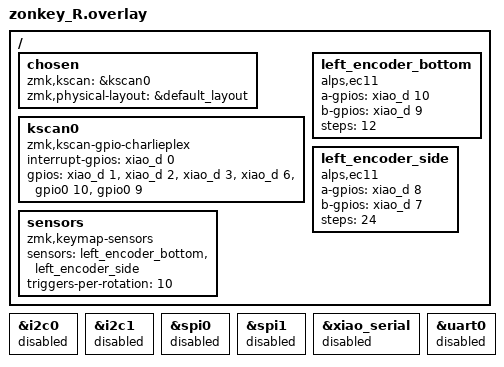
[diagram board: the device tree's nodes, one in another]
#include <dt-bindings/zmk/matrix_transform.h>
#include <dt-bindings/zmk/input_transform.h>
#include <input/processors.dtsi>
#include <zephyr/dt-bindings/input/input-event-codes.h>
#include <physical_layouts.dtsi>
#include "zk.dtsi"

/ {
    chosen {
        zmk,kscan = &kscan0;
        zmk,physical-layout = &default_layout;
        /* I2Cを削除したため zephyr,display は記述しません */
    };

    /* チャーリープレックス・マトリックス設定 */
    kscan0: kscan0 {
        compatible = "zmk,kscan-gpio-charlieplex";
        interrupt-gpios = <&xiao_d 0 (GPIO_ACTIVE_HIGH | GPIO_PULL_DOWN)>;
        gpios
            = <&xiao_d 1 GPIO_ACTIVE_HIGH>
            , <&xiao_d 2 GPIO_ACTIVE_HIGH>
            , <&xiao_d 3 GPIO_ACTIVE_HIGH>
            , <&xiao_d 6 GPIO_ACTIVE_HIGH>
            , <&gpio0 10 GPIO_ACTIVE_HIGH>
            , <&gpio0 9 GPIO_ACTIVE_HIGH>
            ;
    };

    /* エンコーダー1: Bottom */
    left_encoder_bottom: left_encoder_bottom {
        compatible = "alps,ec11";
        a-gpios = <&xiao_d 10 (GPIO_ACTIVE_HIGH | GPIO_PULL_UP)>;
        b-gpios = <&xiao_d 9 (GPIO_ACTIVE_HIGH | GPIO_PULL_UP)>;
        steps = <12>;
        status = "okay";
    };

    /* エンコーダー2: Side */
    left_encoder_side: left_encoder_side {
        compatible = "alps,ec11";
        a-gpios = <&xiao_d 8 (GPIO_ACTIVE_HIGH | GPIO_PULL_UP)>;
        b-gpios = <&xiao_d 7 (GPIO_ACTIVE_HIGH | GPIO_PULL_UP)>;
        steps = <24>;
        status = "okay";
    };

    sensors: sensors {
        compatible = "zmk,keymap-sensors";
        sensors = <&left_encoder_bottom &left_encoder_side>;
        triggers-per-rotation = <10>;
    };

    /* トラックボール関連のノードは削除しました */
};

/* --- 通信機能の無効化 --- */
/* 右手側で使用する SPI1 や I2C1 との衝突を防ぎ、pinctrlエラーを回避します */

&i2c0 { status = "disabled"; };
&i2c1 { status = "disabled"; };
&spi0 { status = "disabled"; };
&spi1 { status = "disabled"; };

/* UART関連の無効化 */
&xiao_serial { status = "disabled"; };
&uart0 { status = "disabled"; };
